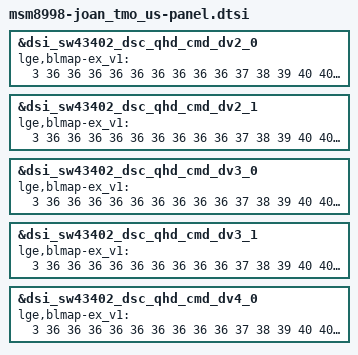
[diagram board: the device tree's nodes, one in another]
/* Copyright (c) 2016, The Linux Foundation. All rights reserved.
 *
 * This program is free software; you can redistribute it and/or modify
 * it under the terms of the GNU General Public License version 2 and
 * only version 2 as published by the Free Software Foundation.
 *
 * This program is distributed in the hope that it will be useful,
 * but WITHOUT ANY WARRANTY; without even the implied warranty of
 * MERCHANTABILITY or FITNESS FOR A PARTICULAR PURPOSE.  See the
 * GNU General Public License for more details.
 */

#include "../msm8998-joan-common/msm8998-joan-common-panel.dtsi"

&dsi_sw43402_dsc_qhd_cmd_dv2_0 {
	lge,blmap-ex_v1 = <
		3
		36 36 36 36 36 36 36 36 36 37 38 39 40 40 41 42 43 44 45 46
		47 48 48 49 50 51 52 53 54 55 56 56 57 58 59 60 62 63 65 67
		68 70 72 73 75 77 78 80 82 83 85 87 88 90 92 93 95 97 98 100
		102 103 105 107 108 110 112 113 115 117 118 120 122 123 125 127 129 131 132 134
		136 138 140 142 144 146 147 149 151 153 155 157 159 160 162 164 166 168 170 172
		174 175 177 179 181 183 185 187 189 191 192 194 196 198 200 201 203 204 205 207
		208 209 211 212 213 214 216 217 218 220 221 222 224 225 225 225 225 225 225 225
		227 228 230 231 233 234 236 238 239 241 242 244 246 247 249 250 252 253 255 255
		255 255 255 255 255 255 255 255 255 255	255 255 255 255 255 255 255 255 255 255
		255 255 255 255 255 255 255 255 255 255	255 255 255 255 255 255 255 255 255 255
		255 255 255 255 255 255 255 255 255 255	255 255 255 255 255 255 255 255 255 255
		255 255 255 255 255 255 255 255 255 255	255 255 255 255 255 255 255 255 255 255
		255 255 255 255 255 255 255 255 255 255	255 255 255 255 255 255 255 255 255 255
		255 255 255 255 255 255 255 255 255 255	255 255 255 255 255 255 255 255 255 255
		255 255 255 255 255 255 255 255 255 255	255 255 255 255 255 255 255 255 255 255
		255 255 255 255 255 255 255 255 255 255	255 255 255 255 255 255 255 255 255 255
		255 255 255 255 255 255 255 255 255 255	255 255 255 255 255 255 255 255 255 255
		255 255 255 255 255 255 255 255 255 255	255 255 255 255 255 255 255 255 255 255
		255 255 255 255 255 255 255 255 255 255	255 255 255 255 255 255 255 255 255 255
		255 255 255 255 255 255 255 255 255 255	255 255 255 255 255 255 255 255 255 255
		255 255 255 255 255 255 255 255 255 255	255 255 255 255 255 255 255 255 255 255
		255 255 255 255 255 255 255 255 255 255	255 255 255 255 255 255 255 255 255 255
		255 255 255 255 255 255 255 255 255 255	255 255 255 255 255 255 255 255 255 255
		255 255 255 255 255 255 255 255 255 255	255 255 255 255 255 255 255 255 255 255
		255 255 255 255 255 255 255 255 255 255	255 255 255 255 255 255 255 255 255 255
		255 255 255 255 255 255 255 255 255 255	255
		>;
};

&dsi_sw43402_dsc_qhd_cmd_dv2_1 {
	lge,blmap-ex_v1 = <
		3
		36 36 36 36 36 36 36 36 36 37 38 39 40 40 41 42 43 44 45 46
		47 48 48 49 50 51 52 53 54 55 56 56 57 58 59 60 62 63 65 67
		68 70 72 73 75 77 78 80 82 83 85 87 88 90 92 93 95 97 98 100
		102 103 105 107 108 110 112 113 115 117 118 120 122 123 125 127 129 131 132 134
		136 138 140 142 144 146 147 149 151 153 155 157 159 160 162 164 166 168 170 172
		174 175 177 179 181 183 185 187 189 191 192 194 196 198 200 201 203 204 205 207
		208 209 211 212 213 214 216 217 218 220 221 222 224 225 225 225 225 225 225 225
		227 228 230 231 233 234 236 238 239 241 242 244 246 247 249 250 252 253 255 255
		255 255 255 255 255 255 255 255 255 255	255 255 255 255 255 255 255 255 255 255
		255 255 255 255 255 255 255 255 255 255	255 255 255 255 255 255 255 255 255 255
		255 255 255 255 255 255 255 255 255 255	255 255 255 255 255 255 255 255 255 255
		255 255 255 255 255 255 255 255 255 255	255 255 255 255 255 255 255 255 255 255
		255 255 255 255 255 255 255 255 255 255	255 255 255 255 255 255 255 255 255 255
		255 255 255 255 255 255 255 255 255 255	255 255 255 255 255 255 255 255 255 255
		255 255 255 255 255 255 255 255 255 255	255 255 255 255 255 255 255 255 255 255
		255 255 255 255 255 255 255 255 255 255	255 255 255 255 255 255 255 255 255 255
		255 255 255 255 255 255 255 255 255 255	255 255 255 255 255 255 255 255 255 255
		255 255 255 255 255 255 255 255 255 255	255 255 255 255 255 255 255 255 255 255
		255 255 255 255 255 255 255 255 255 255	255 255 255 255 255 255 255 255 255 255
		255 255 255 255 255 255 255 255 255 255	255 255 255 255 255 255 255 255 255 255
		255 255 255 255 255 255 255 255 255 255	255 255 255 255 255 255 255 255 255 255
		255 255 255 255 255 255 255 255 255 255	255 255 255 255 255 255 255 255 255 255
		255 255 255 255 255 255 255 255 255 255	255 255 255 255 255 255 255 255 255 255
		255 255 255 255 255 255 255 255 255 255	255 255 255 255 255 255 255 255 255 255
		255 255 255 255 255 255 255 255 255 255	255 255 255 255 255 255 255 255 255 255
		255 255 255 255 255 255 255 255 255 255	255
		>;
};

&dsi_sw43402_dsc_qhd_cmd_dv3_0 {
	lge,blmap-ex_v1 = <
		3
		36 36 36 36 36 36 36 36 36 37 38 39 40 40 41 42 43 44 45 46
		47 48 48 49 50 51 52 53 54 55 56 56 57 58 59 60 62 63 65 67
		68 70 72 73 75 77 78 80 82 83 85 87 88 90 92 93 95 97 98 100
		102 103 105 107 108 110 112 113 115 117 118 120 122 123 125 127 129 131 132 134
		136 138 140 142 144 146 147 149 151 153 155 157 159 160 162 164 166 168 170 172
		174 175 177 179 181 183 185 187 189 191 192 194 196 198 200 201 203 204 205 207
		208 209 211 212 213 214 216 217 218 220 221 222 224 225 225 225 225 225 225 225
		227 228 230 231 233 234 236 238 239 241 242 244 246 247 249 250 252 253 255 255
		255 255 255 255 255 255 255 255 255 255	255 255 255 255 255 255 255 255 255 255
		255 255 255 255 255 255 255 255 255 255	255 255 255 255 255 255 255 255 255 255
		255 255 255 255 255 255 255 255 255 255	255 255 255 255 255 255 255 255 255 255
		255 255 255 255 255 255 255 255 255 255	255 255 255 255 255 255 255 255 255 255
		255 255 255 255 255 255 255 255 255 255	255 255 255 255 255 255 255 255 255 255
		255 255 255 255 255 255 255 255 255 255	255 255 255 255 255 255 255 255 255 255
		255 255 255 255 255 255 255 255 255 255	255 255 255 255 255 255 255 255 255 255
		255 255 255 255 255 255 255 255 255 255	255 255 255 255 255 255 255 255 255 255
		255 255 255 255 255 255 255 255 255 255	255 255 255 255 255 255 255 255 255 255
		255 255 255 255 255 255 255 255 255 255	255 255 255 255 255 255 255 255 255 255
		255 255 255 255 255 255 255 255 255 255	255 255 255 255 255 255 255 255 255 255
		255 255 255 255 255 255 255 255 255 255	255 255 255 255 255 255 255 255 255 255
		255 255 255 255 255 255 255 255 255 255	255 255 255 255 255 255 255 255 255 255
		255 255 255 255 255 255 255 255 255 255	255 255 255 255 255 255 255 255 255 255
		255 255 255 255 255 255 255 255 255 255	255 255 255 255 255 255 255 255 255 255
		255 255 255 255 255 255 255 255 255 255	255 255 255 255 255 255 255 255 255 255
		255 255 255 255 255 255 255 255 255 255	255 255 255 255 255 255 255 255 255 255
		255 255 255 255 255 255 255 255 255 255	255
		>;
};

&dsi_sw43402_dsc_qhd_cmd_dv3_1 {
	lge,blmap-ex_v1 = <
		3
		36 36 36 36 36 36 36 36 36 37 38 39 40 40 41 42 43 44 45 46
		47 48 48 49 50 51 52 53 54 55 56 56 57 58 59 60 62 63 65 67
		68 70 72 73 75 77 78 80 82 83 85 87 88 90 92 93 95 97 98 100
		102 103 105 107 108 110 112 113 115 117 118 120 122 123 125 127 129 131 132 134
		136 138 140 142 144 146 147 149 151 153 155 157 159 160 162 164 166 168 170 172
		174 175 177 179 181 183 185 187 189 191 192 194 196 198 200 201 203 204 205 207
		208 209 211 212 213 214 216 217 218 220 221 222 224 225 225 225 225 225 225 225
		227 228 230 231 233 234 236 238 239 241 242 244 246 247 249 250 252 253 255 255
		255 255 255 255 255 255 255 255 255 255	255 255 255 255 255 255 255 255 255 255
		255 255 255 255 255 255 255 255 255 255	255 255 255 255 255 255 255 255 255 255
		255 255 255 255 255 255 255 255 255 255	255 255 255 255 255 255 255 255 255 255
		255 255 255 255 255 255 255 255 255 255	255 255 255 255 255 255 255 255 255 255
		255 255 255 255 255 255 255 255 255 255	255 255 255 255 255 255 255 255 255 255
		255 255 255 255 255 255 255 255 255 255	255 255 255 255 255 255 255 255 255 255
		255 255 255 255 255 255 255 255 255 255	255 255 255 255 255 255 255 255 255 255
		255 255 255 255 255 255 255 255 255 255	255 255 255 255 255 255 255 255 255 255
		255 255 255 255 255 255 255 255 255 255	255 255 255 255 255 255 255 255 255 255
		255 255 255 255 255 255 255 255 255 255	255 255 255 255 255 255 255 255 255 255
		255 255 255 255 255 255 255 255 255 255	255 255 255 255 255 255 255 255 255 255
		255 255 255 255 255 255 255 255 255 255	255 255 255 255 255 255 255 255 255 255
		255 255 255 255 255 255 255 255 255 255	255 255 255 255 255 255 255 255 255 255
		255 255 255 255 255 255 255 255 255 255	255 255 255 255 255 255 255 255 255 255
		255 255 255 255 255 255 255 255 255 255	255 255 255 255 255 255 255 255 255 255
		255 255 255 255 255 255 255 255 255 255	255 255 255 255 255 255 255 255 255 255
		255 255 255 255 255 255 255 255 255 255	255 255 255 255 255 255 255 255 255 255
		255 255 255 255 255 255 255 255 255 255	255
		>;
};

&dsi_sw43402_dsc_qhd_cmd_dv4_0 {
	lge,blmap-ex_v1 = <
		3
		36 36 36 36 36 36 36 36 36 37 38 39 40 40 41 42 43 44 45 46
		47 48 48 49 50 51 52 53 54 55 56 56 57 58 59 60 62 63 65 67
		68 70 72 73 75 77 78 80 82 83 85 87 88 90 92 93 95 97 98 100
		102 103 105 107 108 110 112 113 115 117 118 120 122 123 125 127 129 131 132 134
		136 138 140 142 144 146 147 149 151 153 155 157 159 160 162 164 166 168 170 172
		174 175 177 179 181 183 185 187 189 191 192 194 196 198 200 201 203 204 205 207
		208 209 211 212 213 214 216 217 218 220 221 222 224 225 225 225 225 225 225 225
		227 228 230 231 233 234 236 238 239 241 242 244 246 247 249 250 252 253 255 255
		255 255 255 255 255 255 255 255 255 255	255 255 255 255 255 255 255 255 255 255
		255 255 255 255 255 255 255 255 255 255	255 255 255 255 255 255 255 255 255 255
		255 255 255 255 255 255 255 255 255 255	255 255 255 255 255 255 255 255 255 255
		255 255 255 255 255 255 255 255 255 255	255 255 255 255 255 255 255 255 255 255
		255 255 255 255 255 255 255 255 255 255	255 255 255 255 255 255 255 255 255 255
		255 255 255 255 255 255 255 255 255 255	255 255 255 255 255 255 255 255 255 255
		255 255 255 255 255 255 255 255 255 255	255 255 255 255 255 255 255 255 255 255
		255 255 255 255 255 255 255 255 255 255	255 255 255 255 255 255 255 255 255 255
		255 255 255 255 255 255 255 255 255 255	255 255 255 255 255 255 255 255 255 255
		255 255 255 255 255 255 255 255 255 255	255 255 255 255 255 255 255 255 255 255
		255 255 255 255 255 255 255 255 255 255	255 255 255 255 255 255 255 255 255 255
		255 255 255 255 255 255 255 255 255 255	255 255 255 255 255 255 255 255 255 255
		255 255 255 255 255 255 255 255 255 255	255 255 255 255 255 255 255 255 255 255
		255 255 255 255 255 255 255 255 255 255	255 255 255 255 255 255 255 255 255 255
		255 255 255 255 255 255 255 255 255 255	255 255 255 255 255 255 255 255 255 255
		255 255 255 255 255 255 255 255 255 255	255 255 255 255 255 255 255 255 255 255
		255 255 255 255 255 255 255 255 255 255	255 255 255 255 255 255 255 255 255 255
		255 255 255 255 255 255 255 255 255 255	255
		>;
};
